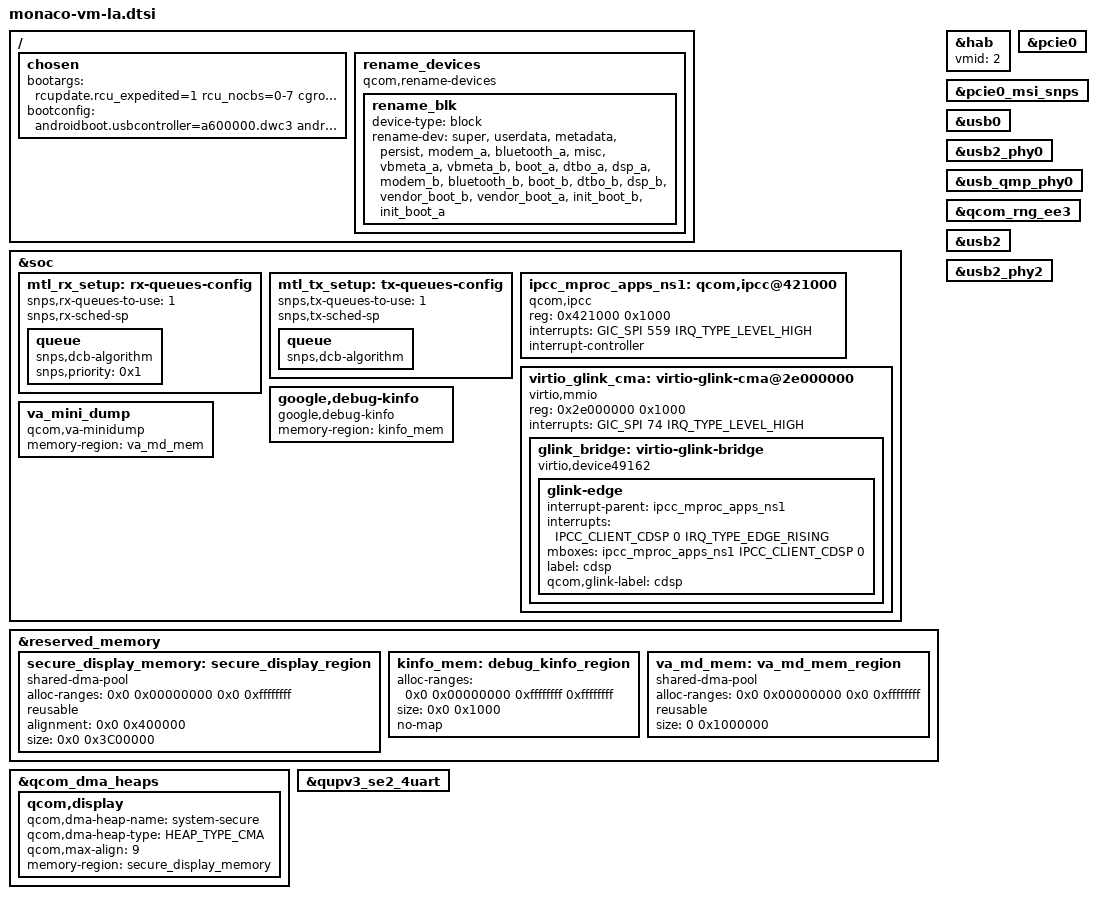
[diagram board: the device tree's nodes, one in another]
// SPDX-License-Identifier: BSD-3-Clause
/*
 * Copyright (c) Qualcomm Technologies, Inc. and/or its subsidiaries.
 */

#include <dt-bindings/soc/qcom,ipcc.h>
/ {
	chosen {
		bootargs = "rcupdate.rcu_expedited=1 rcu_nocbs=0-7 cgroup.memory=nokmem,nosocket kpti=0 qcom_dma_heaps.enable_bitstream_contig_heap=y ufshcd-core.use_mcq_mode=n arm64.nopauth kasan=off msm_show_resume_irq.debug_mask=1";
		bootconfig = "androidboot.usbcontroller=a600000.dwc3 androidboot.fstab_suffix=gen4.qcom androidboot.dtbo_idx=7";
	};

	rename_devices: rename_devices {
		compatible = "qcom,rename-devices";
		rename_blk: rename_blk {
			device-type = "block";
			rename-dev = "super", "userdata", "metadata",
					"persist", "modem_a","bluetooth_a",
					"misc", "vbmeta_a", "vbmeta_b",
					"boot_a", "dtbo_a", "dsp_a",
					"modem_b", "bluetooth_b", "boot_b",
					"dtbo_b", "dsp_b", "vendor_boot_b",
					"vendor_boot_a", "init_boot_b", "init_boot_a";
		};
	};
};

&soc {

	mtl_rx_setup: rx-queues-config {
		snps,rx-queues-to-use = <1>;
		snps,rx-sched-sp;

		queue {
			snps,dcb-algorithm;
			snps,priority = <0x1>;
		};
	};

	mtl_tx_setup: tx-queues-config {
		snps,tx-queues-to-use = <1>;
		snps,tx-sched-sp;
		queue {
			snps,dcb-algorithm;
		};
	};

	ipcc_mproc_apps_ns1: qcom,ipcc@421000 {
		compatible = "qcom,ipcc";
		reg = <0x421000 0x1000>;
		interrupts = <GIC_SPI 559 IRQ_TYPE_LEVEL_HIGH>;
		interrupt-controller;
		#interrupt-cells = <3>;
		#mbox-cells = <2>;
	};

	virtio_glink_cma: virtio-glink-cma@2e000000 {
		compatible = "virtio,mmio";
		reg = <0x2e000000 0x1000>;
		interrupts = <GIC_SPI 74 IRQ_TYPE_LEVEL_HIGH>;

		glink_bridge: virtio-glink-bridge {
			compatible = "virtio,device49162"; /* VIRTIO_ID: 0xC00A */

			glink-edge {
				interrupt-parent = <&ipcc_mproc_apps_ns1>;
				interrupts = <IPCC_CLIENT_CDSP 0 IRQ_TYPE_EDGE_RISING>;
				mboxes = <&ipcc_mproc_apps_ns1 IPCC_CLIENT_CDSP 0>;
				label = "cdsp";
				qcom,glink-label = "cdsp";
			};
		};
	};
};

&reserved_memory {
	secure_display_memory: secure_display_region {
		compatible = "shared-dma-pool";
		alloc-ranges = <0x0 0x00000000 0x0 0xffffffff>;
		reusable;
		alignment = <0x0 0x400000>;
		size = <0x0 0x3C00000>;
	};

	kinfo_mem: debug_kinfo_region {
		alloc-ranges = <0x0 0x00000000 0xffffffff 0xffffffff>;
		size = <0x0 0x1000>;
		no-map;
	};

	va_md_mem: va_md_mem_region {
		compatible = "shared-dma-pool";
		alloc-ranges = <0x0 0x00000000 0x0 0xffffffff>;
		reusable;
		size = <0 0x1000000>;
	};
};

&qcom_dma_heaps {
	qcom,display {
		qcom,dma-heap-name = "system-secure";
		qcom,dma-heap-type = <HEAP_TYPE_CMA>;
		qcom,max-align = <9>;
		memory-region = <&secure_display_memory>;
	};
};

&soc {
	google,debug-kinfo {
		compatible = "google,debug-kinfo";
		memory-region = <&kinfo_mem>;
	};

	va_mini_dump {
		compatible = "qcom,va-minidump";
		memory-region = <&va_md_mem>;
	};
};

&hab {
	vmid = <2>;
};

&pcie0 {
	status = "ok";
};

&pcie0_msi_snps {
	status = "ok";
};

&usb0 {
	status = "ok";
};

&usb2_phy0 {
	status = "ok";
};

&usb_qmp_phy0 {
	status = "ok";
};

&qcom_rng_ee3 {
	status = "ok";
};

&usb2 {
	status = "ok";
};

&usb2_phy2 {
	status = "ok";
};

&qupv3_se2_4uart {
	status = "ok";
};
